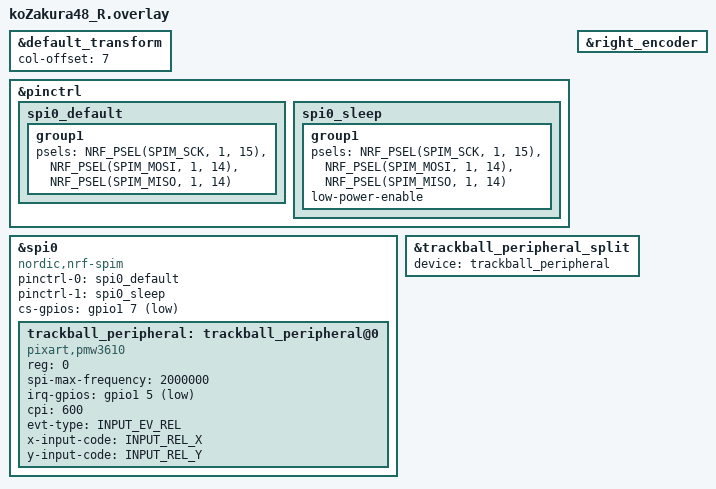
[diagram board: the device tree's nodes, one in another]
#include "koZakura48.dtsi"
#include <behaviors/battery_history_request.dtsi>

&default_transform {
    col-offset = <7>;
};

//追加文
&pinctrl {
    spi0_default: spi0_default {    //通常時(SPI通信中)のピン構成
        group1 {
            psels = <NRF_PSEL(SPIM_SCK, 1, 15)>, //P1.15を指定(SCLK)
                <NRF_PSEL(SPIM_MOSI, 1, 14)>,    //P1.14を指定(SDIOだからMOSI,MISO両方の役割を担う)
                <NRF_PSEL(SPIM_MISO, 1, 14)>;
        };
    };

    spi0_sleep: spi0_sleep {    //スリープ時のピン構成(省電力)
        group1 {
            psels = <NRF_PSEL(SPIM_SCK, 1, 15)>,
                <NRF_PSEL(SPIM_MOSI, 1, 14)>,
                <NRF_PSEL(SPIM_MISO, 1, 14)>;
            low-power-enable;
        };
    };
};

#include <zephyr/dt-bindings/input/input-event-codes.h>
&spi0 {
    status = "okay";
    compatible = "nordic,nrf-spim";
    pinctrl-0 = <&spi0_default>;
    pinctrl-1 = <&spi0_sleep>;
    pinctrl-names = "default", "sleep";
    cs-gpios = <&gpio1 7 GPIO_ACTIVE_LOW>; //P1.03とチェンジ

    trackball_peripheral: trackball_peripheral@0 {
        status = "okay";
        compatible = "pixart,pmw3610";
        reg = <0>;
        spi-max-frequency = <2000000>;
        irq-gpios = <&gpio1 5 (GPIO_ACTIVE_LOW | GPIO_PULL_UP)>;
        cpi = <600>;
        evt-type = <INPUT_EV_REL>;
        x-input-code = <INPUT_REL_X>;
        y-input-code = <INPUT_REL_Y>;
    };
};

&right_encoder {
    status = "okay";
};

// Overrides for the input-split child node
&trackball_peripheral_split {
    device = <&trackball_peripheral>;
};
